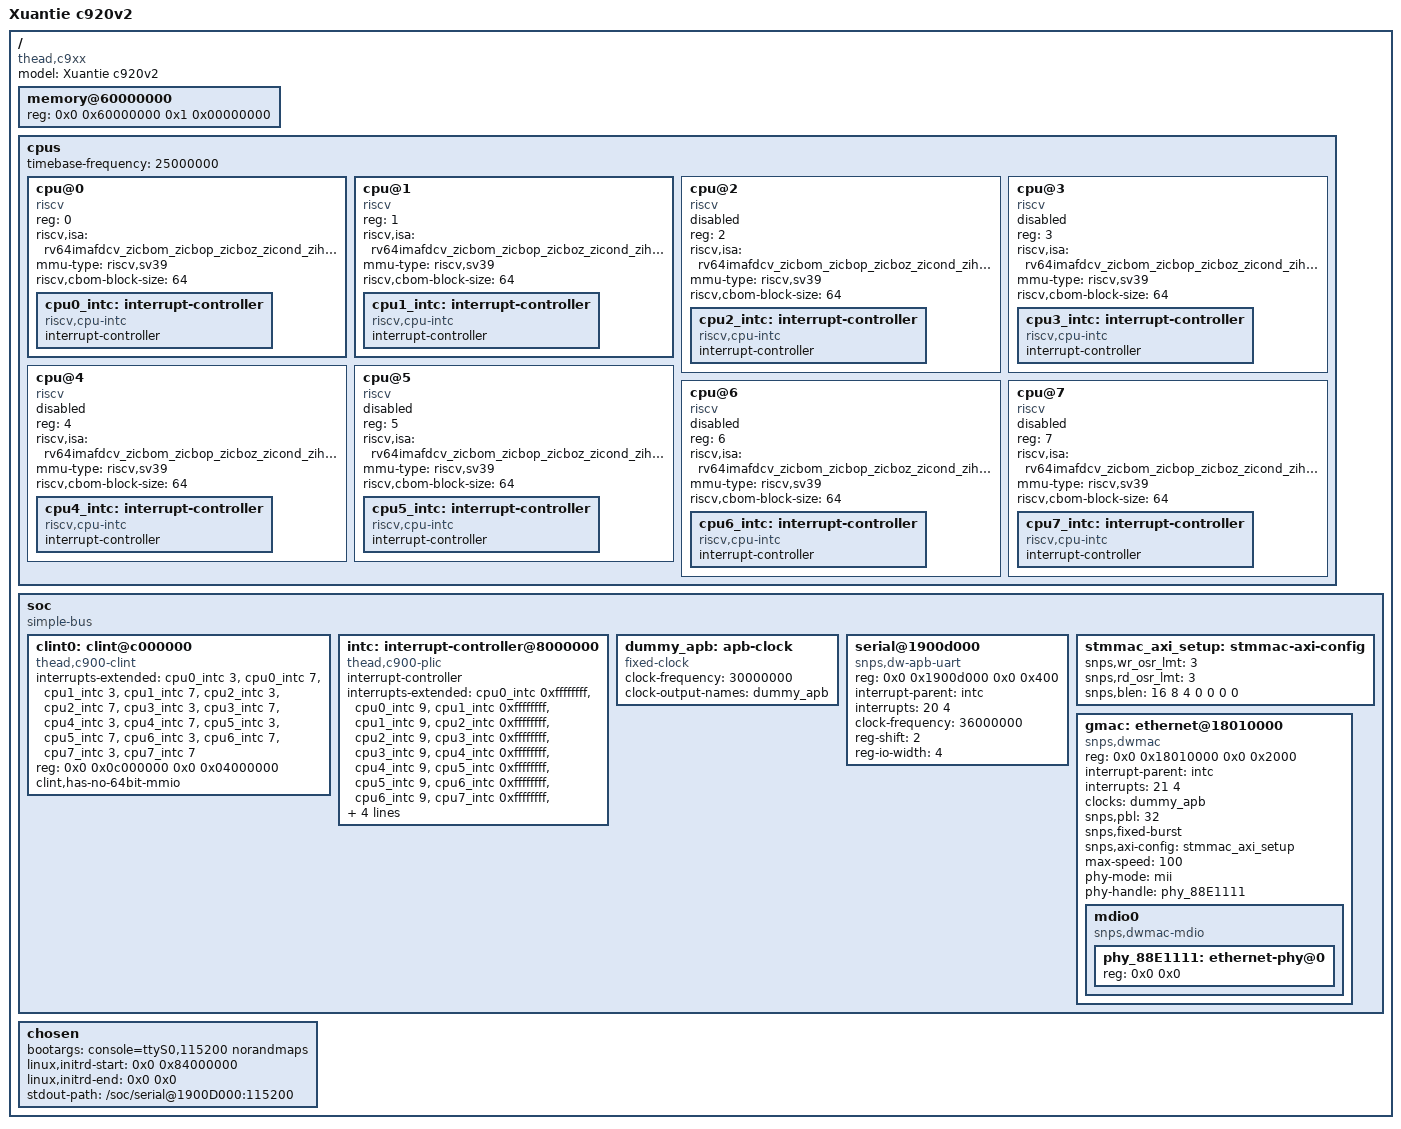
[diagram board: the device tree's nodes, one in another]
/dts-v1/;
/ {
	model = "Xuantie c920v2";
	compatible = "thead,c9xx";
	#address-cells = <2>;
	#size-cells = <2>;

	memory@60000000 {
		device_type = "memory";
		reg = <0x0 0x60000000 0x1 0x00000000>;
	};

	cpus {
		#address-cells = <1>;
		#size-cells = <0>;
		timebase-frequency = <25000000>;
		cpu@0 {
			device_type = "cpu";
			reg = <0>;
			status = "okay";
			compatible = "riscv";
			riscv,isa = "rv64imafdcv_zicbom_zicbop_zicboz_zicond_zihintntl_zihintpause_zawrs_zfa_zfbfmin_zfh_zca_zcb_zcd_zba_zbb_zbc_zbs_zvfbfmin_zvfbfwma_svinval_svpbmt_xtheadc_xtheadvdot";
			mmu-type = "riscv,sv39";
			riscv,cbom-block-size = <64>;
			cpu0_intc: interrupt-controller {
				#interrupt-cells = <1>;
				compatible = "riscv,cpu-intc";
				interrupt-controller;
			};
		};
		cpu@1 {
			device_type = "cpu";
			reg = <1>;
			status = "okay";
			compatible = "riscv";
			riscv,isa = "rv64imafdcv_zicbom_zicbop_zicboz_zicond_zihintntl_zihintpause_zawrs_zfa_zfbfmin_zfh_zca_zcb_zcd_zba_zbb_zbc_zbs_zvfbfmin_zvfbfwma_svinval_svpbmt_xtheadc_xtheadvdot";
			mmu-type = "riscv,sv39";
			riscv,cbom-block-size = <64>;
			cpu1_intc: interrupt-controller {
				#interrupt-cells = <1>;
				compatible = "riscv,cpu-intc";
				interrupt-controller;
			};
		};
		cpu@2 {
			device_type = "cpu";
			reg = <2>;
			status = "skip";
			compatible = "riscv";
			riscv,isa = "rv64imafdcv_zicbom_zicbop_zicboz_zicond_zihintntl_zihintpause_zawrs_zfa_zfbfmin_zfh_zca_zcb_zcd_zba_zbb_zbc_zbs_zvfbfmin_zvfbfwma_svinval_svpbmt_xtheadc_xtheadvdot";
			mmu-type = "riscv,sv39";
			riscv,cbom-block-size = <64>;
			cpu2_intc: interrupt-controller {
				#interrupt-cells = <1>;
				compatible = "riscv,cpu-intc";
				interrupt-controller;
			};
		};
		cpu@3 {
			device_type = "cpu";
			reg = <3>;
			status = "skip";
			compatible = "riscv";
			riscv,isa = "rv64imafdcv_zicbom_zicbop_zicboz_zicond_zihintntl_zihintpause_zawrs_zfa_zfbfmin_zfh_zca_zcb_zcd_zba_zbb_zbc_zbs_zvfbfmin_zvfbfwma_svinval_svpbmt_xtheadc_xtheadvdot";
			mmu-type = "riscv,sv39";
			riscv,cbom-block-size = <64>;
			cpu3_intc: interrupt-controller {
				#interrupt-cells = <1>;
				compatible = "riscv,cpu-intc";
				interrupt-controller;
			};
		};
		cpu@4 {
			device_type = "cpu";
			reg = <4>;
			status = "skip";
			compatible = "riscv";
			riscv,isa = "rv64imafdcv_zicbom_zicbop_zicboz_zicond_zihintntl_zihintpause_zawrs_zfa_zfbfmin_zfh_zca_zcb_zcd_zba_zbb_zbc_zbs_zvfbfmin_zvfbfwma_svinval_svpbmt_xtheadc_xtheadvdot";
			mmu-type = "riscv,sv39";
			riscv,cbom-block-size = <64>;
			cpu4_intc: interrupt-controller {
				#interrupt-cells = <1>;
				compatible = "riscv,cpu-intc";
				interrupt-controller;
			};
		};
		cpu@5 {
			device_type = "cpu";
			reg = <5>;
			status = "skip";
			compatible = "riscv";
			riscv,isa = "rv64imafdcv_zicbom_zicbop_zicboz_zicond_zihintntl_zihintpause_zawrs_zfa_zfbfmin_zfh_zca_zcb_zcd_zba_zbb_zbc_zbs_zvfbfmin_zvfbfwma_svinval_svpbmt_xtheadc_xtheadvdot";
			mmu-type = "riscv,sv39";
			riscv,cbom-block-size = <64>;
			cpu5_intc: interrupt-controller {
				#interrupt-cells = <1>;
				compatible = "riscv,cpu-intc";
				interrupt-controller;
			};
		};
		cpu@6 {
			device_type = "cpu";
			reg = <6>;
			status = "skip";
			compatible = "riscv";
			riscv,isa = "rv64imafdcv_zicbom_zicbop_zicboz_zicond_zihintntl_zihintpause_zawrs_zfa_zfbfmin_zfh_zca_zcb_zcd_zba_zbb_zbc_zbs_zvfbfmin_zvfbfwma_svinval_svpbmt_xtheadc_xtheadvdot";
			mmu-type = "riscv,sv39";
			riscv,cbom-block-size = <64>;
			cpu6_intc: interrupt-controller {
				#interrupt-cells = <1>;
				compatible = "riscv,cpu-intc";
				interrupt-controller;
			};
		};
		cpu@7 {
			device_type = "cpu";
			reg = <7>;
			status = "skip";
			compatible = "riscv";
			riscv,isa = "rv64imafdcv_zicbom_zicbop_zicboz_zicond_zihintntl_zihintpause_zawrs_zfa_zfbfmin_zfh_zca_zcb_zcd_zba_zbb_zbc_zbs_zvfbfmin_zvfbfwma_svinval_svpbmt_xtheadc_xtheadvdot";
			mmu-type = "riscv,sv39";
			riscv,cbom-block-size = <64>;
			cpu7_intc: interrupt-controller {
				#interrupt-cells = <1>;
				compatible = "riscv,cpu-intc";
				interrupt-controller;
			};
		};
	};
 
	soc {
		#address-cells = <2>;
		#size-cells = <2>;
		compatible = "simple-bus";
		ranges;

		clint0: clint@c000000 {
			compatible = "thead,c900-clint";
			interrupts-extended = <
				&cpu0_intc  3 &cpu0_intc  7
				&cpu1_intc  3 &cpu1_intc  7
				&cpu2_intc  3 &cpu2_intc  7
				&cpu3_intc  3 &cpu3_intc  7
				&cpu4_intc  3 &cpu4_intc  7
				&cpu5_intc  3 &cpu5_intc  7
				&cpu6_intc  3 &cpu6_intc  7
				&cpu7_intc  3 &cpu7_intc  7
				>;
			reg = <0x0 0x0c000000 0x0 0x04000000>;
			clint,has-no-64bit-mmio;
		};

		intc: interrupt-controller@8000000 {
			#address-cells = <0>;
			#interrupt-cells = <2>;
			compatible = "thead,c900-plic";
			interrupt-controller;
			interrupts-extended = <
				&cpu0_intc  0xffffffff &cpu0_intc  9
				&cpu1_intc  0xffffffff &cpu1_intc  9
				&cpu2_intc  0xffffffff &cpu2_intc  9
				&cpu3_intc  0xffffffff &cpu3_intc  9
				&cpu4_intc  0xffffffff &cpu4_intc  9
				&cpu5_intc  0xffffffff &cpu5_intc  9
				&cpu6_intc  0xffffffff &cpu6_intc  9
				&cpu7_intc  0xffffffff &cpu7_intc  9
				>;
			reg = <0x0 0x08000000 0x0 0x04000000>;
			reg-names = "control";
			riscv,max-priority = <7>;
			riscv,ndev = <80>;
		};

		dummy_apb: apb-clock {
			#clock-cells = <0>;
			compatible = "fixed-clock";
			clock-frequency = <30000000>;
			clock-output-names = "dummy_apb";
		};

		serial@1900d000 {
			compatible = "snps,dw-apb-uart";
			reg = <0x0 0x1900d000 0x0 0x400>;
			interrupt-parent = <&intc>;
			interrupts = <20 4>;
			clock-frequency = <36000000>;
			clock-names = "baudclk";
			reg-shift = <2>;
			reg-io-width = <4>;
		};

		stmmac_axi_setup: stmmac-axi-config{
			snps,wr_osr_lmt = <3>;
			snps,rd_osr_lmt = <3>;
			snps,blen = <16 8 4 0 0 0 0> ;
		};
		gmac: ethernet@18010000 {
			compatible = "snps,dwmac";
			reg = <0x0 0x18010000 0x0 0x2000>;
			interrupt-parent = <&intc>;
			interrupts = <21 4>;
			interrupt-names = "macirq";
			clocks = <&dummy_apb>;
			clock-names = "stmmaceth";
			snps,pbl = <32>;
			snps,fixed-burst;
			snps,axi-config = <&stmmac_axi_setup>;
			max-speed = <100>;
			phy-mode = "mii";
			phy-handle = <&phy_88E1111>;
			mdio0 {
				#address-cells = <1>;
				#size-cells = <0>;
				compatible = "snps,dwmac-mdio";

				phy_88E1111: ethernet-phy@0 {
					reg = <0x0 0x0>;
				};
			};
		};
	};

	chosen {
		bootargs = "console=ttyS0,115200 norandmaps";
		linux,initrd-start = <0x0 0x84000000>;
		linux,initrd-end = <0x0 0x0>;
		stdout-path = "/soc/serial@1900D000:115200";
	};
};
